# ATmegaS128 register map
Vendor: Atmel; File version: 1.0
CPU: other r0p0, little endian, no MPU, no FPU, 4 interrupt priority bits
Registers are 8-bit, read-write, reset 0x0 unless marked. A register's access mark holds for its fields unless they carry their own. Offsets are from the block's base; [hi:lo] are bit positions.

## TC1 — Timer/Counter, 16-bit
Base 0x00800040
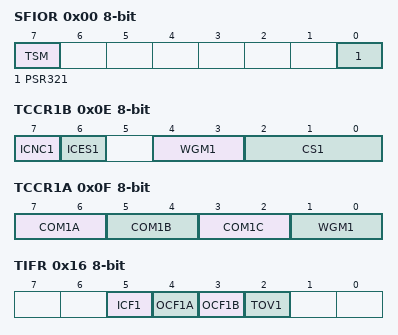
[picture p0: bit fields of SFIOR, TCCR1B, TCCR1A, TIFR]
0x00 SFIOR — Special Function IO Register
  [7] TSM — Timer/Counter Synchronization Mode
  [0] PSR321 — Prescaler Reset, T/C3, T/C2, T/C1
0x06 ICR1 16-bit (reset mask 0xFF) — Timer/Counter1 Input Capture Register Bytes
0x08 OCR1B 16-bit (reset mask 0xFF) — Timer/Counter1 Output Compare Register Bytes
0x0A OCR1A 16-bit (reset mask 0xFF) — Timer/Counter1 Output Compare Register Bytes
0x0C TCNT1 16-bit (reset mask 0xFF) — Timer/Counter1 Bytes
0x0E TCCR1B — Timer/Counter1 Control Register B
  [7] ICNC1 — Input Capture 1 Noise Canceler
  [6] ICES1 — Input Capture 1 Edge Select
  [4:3] WGM1 — Waveform Generation Mode
  [2:0] CS1 — Clock Select1 bits
    0=NO_CLOCK_SOURCE_STOPPED; 1=RUNNING_NO_PRESCALING; 2=RUNNING_CLK_8; 3=RUNNING_CLK_64; 4=RUNNING_CLK_256; 5=RUNNING_CLK_1024; 6=RUNNING_EXTCLK_TN_FALLING_EDGE; 7=RUNNING_EXTCLK_TN_RISING_EDGE
0x0F TCCR1A — Timer/Counter1 Control Register A
  [7:6] COM1A — Compare Output Mode 1A, bits
  [5:4] COM1B — Compare Output Mode 1B, bits
  [3:2] COM1C — Compare Output Mode 1C, bits
  [1:0] WGM1 — Waveform Generation Mode Bits
0x16 TIFR — Timer/Counter Interrupt Flag register (read-only for debugger)
  [5] ICF1 — Input Capture Flag 1
  [4] OCF1A — Output Compare Flag 1A
  [3] OCF1B — Output Compare Flag 1B
  [2] TOV1 — Timer/Counter1 Overflow Flag
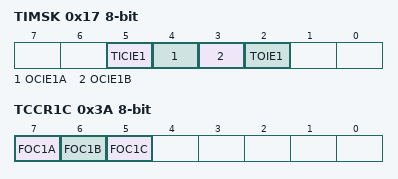
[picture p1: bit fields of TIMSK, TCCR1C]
0x17 TIMSK — Timer/Counter Interrupt Mask Register
  [5] TICIE1 — Timer/Counter1 Input Capture Interrupt Enable
  [4] OCIE1A — Timer/Counter1 Output CompareA Match Interrupt Enable
  [3] OCIE1B — Timer/Counter1 Output CompareB Match Interrupt Enable
  [2] TOIE1 — Timer/Counter1 Overflow Interrupt Enable
0x38 OCR1C 16-bit (reset mask 0xFF) — Timer/Counter1 Output Compare Register Bytes
0x3A TCCR1C — Timer/Counter1 Control Register C
  [7] FOC1A — Force Output Compare for channel A
  [6] FOC1B — Force Output Compare for channel B
  [5] FOC1C — Force Output Compare for channel C
0x3C ETIFR — Extended Timer/Counter Interrupt Flag register (read-only for debugger)
  [0] OCF1C — Timer/Counter 1, Output Compare C Match Flag
0x3D ETIMSK — Extended Timer/Counter Interrupt Mask Register
  [0] OCIE1C — Timer/Counter 1, Output Compare Match C Interrupt Enable

## TC2 — Timer/Counter, 8-bit
Base 0x00800043
0x00 OCR2 — Output Compare Register
0x01 TCNT2 — Timer/Counter Register
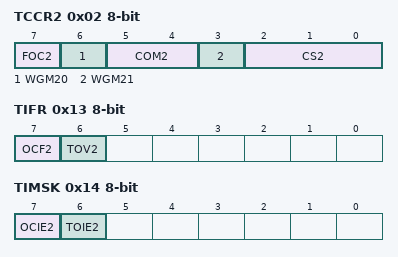
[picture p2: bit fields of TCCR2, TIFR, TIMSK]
0x02 TCCR2 — Timer/Counter Control Register
  [7] FOC2 — Force Output Compare
  [6] WGM20 — Waveform Generation Mode
    0=NORMAL; 1=CTC
  [5:4] COM2 — Compare Match Output Mode
  [3] WGM21 — Waveform Generation Mode
  [2:0] CS2 — Clock Select
    0=NO_CLOCK_SOURCE_STOPPED; 1=RUNNING_NO_PRESCALING; 2=RUNNING_CLK_8; 3=RUNNING_CLK_64; 4=RUNNING_CLK_256; 5=RUNNING_CLK_1024; 6=RUNNING_EXTCLK_TN_FALLING_EDGE; 7=RUNNING_EXTCLK_TN_RISING_EDGE
0x13 TIFR — Timer/Counter Interrupt Flag Register (read-only for debugger)
  [7] OCF2 — Output Compare Flag 2
  [6] TOV2 — Timer/Counter2 Overflow Flag
0x14 TIMSK
  [7] OCIE2, [6] TOIE2

## TC3 — Timer/Counter, 16-bit
Base 0x00800040
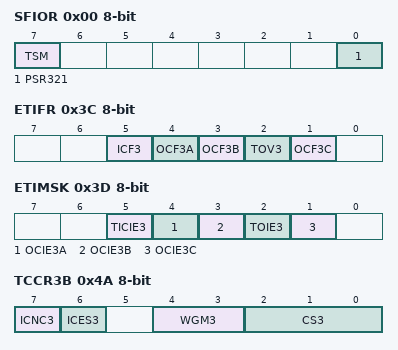
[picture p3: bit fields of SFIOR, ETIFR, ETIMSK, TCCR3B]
0x00 SFIOR — Special Function IO Register
  [7] TSM — Timer/Counter Synchronization Mode
  [0] PSR321 — Prescaler Reset, T/C3, T/C2, T/C1
0x3C ETIFR — Extended Timer/Counter Interrupt Flag register (read-only for debugger)
  [5] ICF3 — Input Capture Flag 3
  [4] OCF3A — Output Compare Flag 3A
  [3] OCF3B — Output Compare Flag 3B
  [2] TOV3 — Timer/Counter3 Overflow Flag
  [1] OCF3C — Timer/Counter3 Output Compare C Match Flag
0x3D ETIMSK — Extended Timer/Counter Interrupt Mask Register
  [5] TICIE3 — Timer/Counter3 Input Capture Interrupt Enable
  [4] OCIE3A — Timer/Counter3 Output CompareA Match Interrupt Enable
  [3] OCIE3B — Timer/Counter3 Output CompareB Match Interrupt Enable
  [2] TOIE3 — Timer/Counter3 Overflow Interrupt Enable
  [1] OCIE3C — Timer/Counter3, Output Compare Match Interrupt Enable
0x40 ICR3 16-bit (reset mask 0xFF) — Timer/Counter3 Input Capture Register Bytes
0x42 OCR3C 16-bit (reset mask 0xFF) — Timer/Counter3 Output compare Register C Bytes
0x44 OCR3B 16-bit (reset mask 0xFF) — Timer/Counter3 Output Compare Register B Bytes
0x46 OCR3A 16-bit (reset mask 0xFF) — Timer/Counter3 Output Compare Register A Bytes
0x48 TCNT3 16-bit (reset mask 0xFF) — Timer/Counter3 Bytes
0x4A TCCR3B — Timer/Counter3 Control Register B
  [7] ICNC3 — Input Capture 3 Noise Canceler
  [6] ICES3 — Input Capture 3 Edge Select
  [4:3] WGM3 — Waveform Generation Mode
  [2:0] CS3 — Clock Select3 bits
    0=NO_CLOCK_SOURCE_STOPPED; 1=RUNNING_NO_PRESCALING; 2=RUNNING_CLK_8; 3=RUNNING_CLK_64; 4=RUNNING_CLK_256; 5=RUNNING_CLK_1024; 6=RUNNING_EXTCLK_TN_FALLING_EDGE; 7=RUNNING_EXTCLK_TN_RISING_EDGE
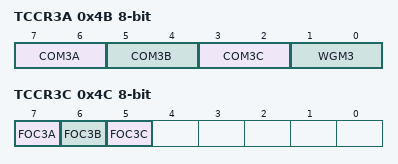
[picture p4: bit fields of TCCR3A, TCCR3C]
0x4B TCCR3A — Timer/Counter3 Control Register A
  [7:6] COM3A — Compare Output Mode 3A, bits
  [5:4] COM3B — Compare Output Mode 3B, bits
  [3:2] COM3C — Compare Output Mode 3C, bits
  [1:0] WGM3 — Waveform Generation Mode Bits
0x4C TCCR3C — Timer/Counter3 Control Register C
  [7] FOC3A — Force Output Compare for channel A
  [6] FOC3B — Force Output Compare for channel B
  [5] FOC3C — Force Output Compare for channel C
